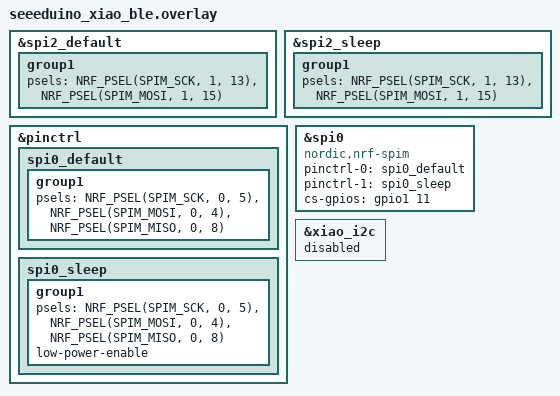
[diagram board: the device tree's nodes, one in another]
&spi2_default {
	group1 {
		psels = <NRF_PSEL(SPIM_SCK, 1, 13)>, // D8 (pin 9)
			<NRF_PSEL(SPIM_MOSI, 1, 15)>; // D10 (pin 11)
	};
};

&spi2_sleep {
	group1 {
		psels = <NRF_PSEL(SPIM_SCK, 1, 13)>,
			<NRF_PSEL(SPIM_MOSI, 1, 15)>;
	};
};

&pinctrl {
	spi0_default: spi0_default {
    	group1 {
      		psels = <NRF_PSEL(SPIM_SCK, 0, 5)>,
        		<NRF_PSEL(SPIM_MOSI, 0, 4)>,
        		<NRF_PSEL(SPIM_MISO, 0, 8)>;
    	};
  	};
  	spi0_sleep: spi0_sleep {
    	group1 {
      		psels = <NRF_PSEL(SPIM_SCK, 0, 5)>, // D5
        		<NRF_PSEL(SPIM_MOSI, 0, 4)>, // D4
        		<NRF_PSEL(SPIM_MISO, 0, 8)>;
      			low-power-enable;
    	};
  	};
};

nice_view_spi: &spi0 {
    compatible = "nordic,nrf-spim";
    pinctrl-0 = <&spi0_default>;
    pinctrl-1 = <&spi0_sleep>;
    pinctrl-names = "default", "sleep";
    cs-gpios = <&gpio1 11 GPIO_ACTIVE_HIGH>; // D6
};

&xiao_i2c {
    status = "disabled";
};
